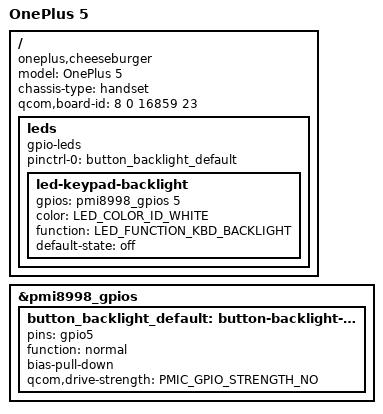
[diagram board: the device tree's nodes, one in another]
#include <dt-bindings/leds/common.h>
#include "msm8998-oneplus-common.dtsi"
/ {
	model = "OnePlus 5";
	compatible = "oneplus,cheeseburger", "qcom,msm8998";
	chassis-type = "handset";
	qcom,board-id = <8 0 16859 23>;
	leds {
		compatible = "gpio-leds";
		pinctrl-names = "default";
		pinctrl-0 = <&button_backlight_default>;
		led-keypad-backlight {
			gpios = <&pmi8998_gpios 5 GPIO_ACTIVE_HIGH>;
			color = <LED_COLOR_ID_WHITE>;
			function = LED_FUNCTION_KBD_BACKLIGHT;
			default-state = "off";
		};
	};
};
&pmi8998_gpios {
	button_backlight_default: button-backlight-state {
		pins = "gpio5";
		function = "normal";
		bias-pull-down;
		qcom,drive-strength = <PMIC_GPIO_STRENGTH_NO>;
	};
};
